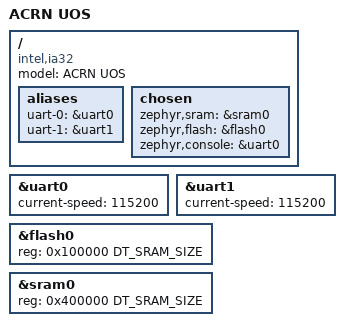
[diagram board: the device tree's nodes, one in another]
/*
 * Copyright (c) 2018 Intel Corporation
 *
 * SPDX-License-Identifier: Apache-2.0
 */

/dts-v1/;

#define DT_FLASH_SIZE		__SIZE_K(8192)
#define DT_SRAM_SIZE		__SIZE_K(8192)

#include <ia32.dtsi>

/ {
	model = "ACRN UOS";
	compatible = "intel,ia32";

	aliases {
		uart-0 = &uart0;
		uart-1 = &uart1;
	};

	chosen {
		zephyr,sram = &sram0;
		zephyr,flash = &flash0;
		zephyr,console = &uart0;
	};
};

&uart0 {
	status = "ok";
	current-speed = <115200>;
};

&uart1 {
	status = "ok";
	current-speed = <115200>;
};

&flash0 {
    reg = <0x100000 DT_SRAM_SIZE>;
};

&sram0 {
    reg = <0x400000 DT_SRAM_SIZE>;
};
